# AVR128DB28 register map
Vendor: Atmel; File version: 1.0
CPU: other r0p0, little endian, no MPU, no FPU, 4 interrupt priority bits
Registers are 8-bit, read-write, reset 0x0 unless marked. A register's access mark holds for its fields unless they carry their own. Offsets are from the block's base; [hi:lo] are bit positions; {n}, {i} and the like mark numbered series.

## ADC0 — Analog to Digital Converter
Base 0x00800600
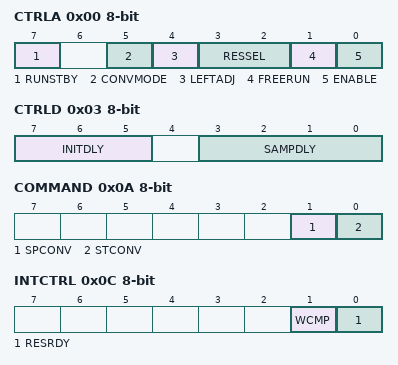
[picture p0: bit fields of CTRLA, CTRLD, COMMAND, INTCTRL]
0x00 CTRLA — Control A
  [7] RUNSTBY — Run standby mode
  [5] CONVMODE — Conversion mode
    0=SINGLEENDED (Single-Ended mode); 1=DIFF (Differential mode)
  [4] LEFTADJ — Left adjust result
  [3:2] RESSEL — Resolution selection
    0=12BIT (12-bit mode); 1=10BIT (10-bit mode)
  [1] FREERUN — Free running mode
  [0] ENABLE — ADC Enable
0x01 CTRLB — Control B
  [2:0] SAMPNUM — Accumulation Samples
    0=NONE (No accumulation); 1=ACC2 (2 results accumulated); 2=ACC4 (4 results accumulated); 3=ACC8 (8 results accumulated); 4=ACC16 (16 results accumulated); 5=ACC32 (32 results accumulated); 6=ACC64 (64 results accumulated); 7=ACC128 (128 results accumulated)
0x02 CTRLC — Control C
  [3:0] PRESC — Clock Pre-scaler
    0=DIV2 (CLK_PER divided by 2); 1=DIV4 (CLK_PER divided by 4); 2=DIV8 (CLK_PER divided by 8); 3=DIV12 (CLK_PER divided by 12); 4=DIV16 (CLK_PER divided by 16); 5=DIV20 (CLK_PER divided by 20); 6=DIV24 (CLK_PER divided by 24); 7=DIV28 (CLK_PER divided by 28); 8=DIV32 (CLK_PER divided by 32); 9=DIV48 (CLK_PER divided by 48); 10=DIV64 (CLK_PER divided by 64); 11=DIV96 (CLK_PER divided by 96); 12=DIV128 (CLK_PER divided by 128); 13=DIV256 (CLK_PER divided by 256)
0x03 CTRLD — Control D
  [7:5] INITDLY — Initial Delay Selection
    0=DLY0 (Delay 0 CLK_ADC cycles); 1=DLY16 (Delay 16 CLK_ADC cycles); 2=DLY32 (Delay 32 CLK_ADC cycles); 3=DLY64 (Delay 64 CLK_ADC cycles); 4=DLY128 (Delay 128 CLK_ADC cycles); 5=DLY256 (Delay 256 CLK_ADC cycles)
  [3:0] SAMPDLY — Sampling Delay Selection
    {v}=DLY{v} (Delay {v} CLK_ADC cycles) (v=0..15)
0x04 CTRLE — Control E
  [2:0] WINCM — Window Comparator Mode
    0=NONE (No Window Comparison); 1=BELOW (Below Window); 2=ABOVE (Above Window); 3=INSIDE (Inside Window); 4=OUTSIDE (Outside Window)
0x05 SAMPCTRL — Sample Control
  [7:0] SAMPLEN — Sample lenght
0x08 MUXPOS — Positive mux input
  [6:0] MUXPOS — Analog Channel Selection Bits
    {v}=AIN{v} (ADC input pin {v}) (v=0..21); 64=GND (Ground); 66=TEMPSENSE (Temperature sensor); 68=VDDDIV10 (VDD/10); 69=VDDIO2DIV10 (VDDIO2/10); 72=DAC0; 73=DACREF0 (AC0 DAC Voltage Reference); 74=DACREF1 (AC1 DAC Voltage Reference); 75=DACREF2 (AC2 DAC Voltage Reference)
0x09 MUXNEG — Negative mux input
  [6:0] MUXNEG — Analog Channel Selection Bits
    {v}=AIN{v} (ADC input pin {v}) (v=0..15); 64=GND (Ground); 72=DAC0
0x0A COMMAND
  [1] SPCONV — Stop Conversion
  [0] STCONV — Start Conversion
0x0B EVCTRL — Event Control
  [0] STARTEI — Start Event Input Enable
0x0C INTCTRL — Interrupt Control
  [1] WCMP — Window Comparator Interrupt Enable
  [0] RESRDY — Result Ready Interrupt Enable
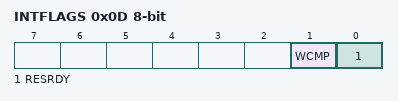
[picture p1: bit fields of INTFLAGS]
0x0D INTFLAGS — Interrupt Flags
  [1] WCMP — Window Comparator Flag
  [0] RESRDY — Result Ready Flag
0x0E DBGCTRL — Debug Control
  [0] DBGRUN — Debug run
0x0F TEMP — Temporary Data
  [7:0] TEMP — Temporary
0x10 RES 16-bit ro (reset mask 0xFF) — ADC Accumulator Result
0x12 WINLT 16-bit (reset mask 0xFF) — Window comparator low threshold
0x14 WINHT 16-bit (reset mask 0xFF) — Window comparator high threshold

## BOD — Bod interface
Base 0x008000A0
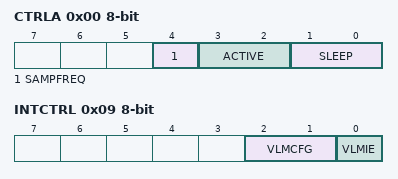
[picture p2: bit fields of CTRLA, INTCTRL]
0x00 CTRLA — Control A
  [4] SAMPFREQ ro — Sample frequency
    0=128HZ (128Hz sampling frequency); 1=32HZ (32Hz sampling frequency)
  [3:2] ACTIVE ro — Operation in active mode
    0=DIS (Disabled); 1=ENABLED; 2=SAMPLED; 3=ENWAKE (Enabled with wake-up halted until BOD is ready)
  [1:0] SLEEP — Operation in sleep mode
    0=DIS (Disabled); 1=ENABLED; 2=SAMPLED
0x01 CTRLB — Control B
  [2:0] LVL ro — Bod level
    0=BODLEVEL0 (1.9 V); 1=BODLEVEL1 (2.45 V); 2=BODLEVEL2 (2.7 V); 3=BODLEVEL3 (2.85 V)
0x08 VLMCTRLA — Voltage level monitor Control
  [1:0] VLMLVL — voltage level monitor level
    0=OFF (VLM Disabled); 1=5ABOVE (VLM threshold 5% above BOD level); 2=15ABOVE (VLM threshold 15% above BOD level); 3=25ABOVE (VLM threshold 25% above BOD level)
0x09 INTCTRL — Voltage level monitor interrupt Control
  [2:1] VLMCFG — Configuration
    0=FALLING (VDD falls below VLM threshold); 1=RISING (VDD rises above VLM threshold); 2=BOTH (VDD crosses VLM threshold)
  [0] VLMIE — voltage level monitor interrrupt enable
0x0A INTFLAGS — Voltage level monitor interrupt Flags
  [0] VLMIF — Voltage level monitor interrupt flag
0x0B STATUS — Voltage level monitor status
  [0] VLMS ro
    0=ABOVE (The voltage is above the VLM threshold level); 1=BELOW (The voltage is below the VLM threshold level)
